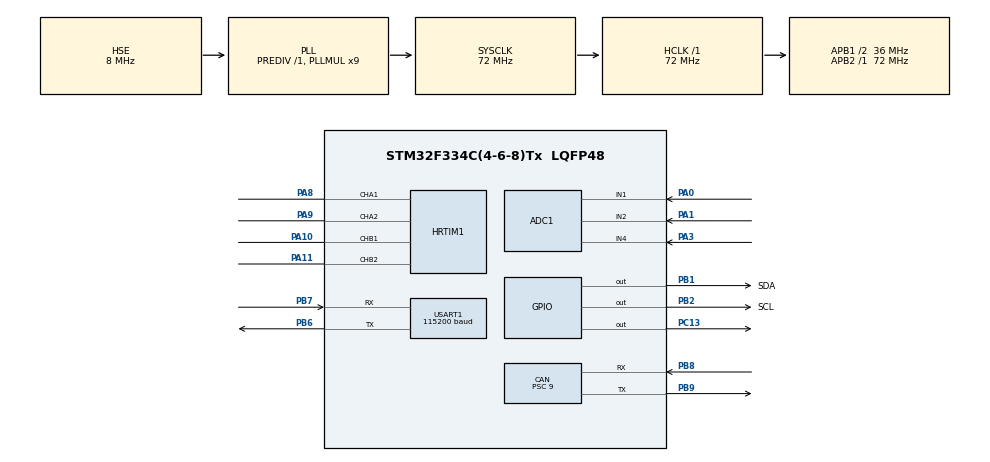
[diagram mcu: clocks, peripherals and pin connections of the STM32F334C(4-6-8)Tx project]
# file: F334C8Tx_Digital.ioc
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ADC1.Channel-0\#ChannelRegularConversion=ADC_CHANNEL_1
ADC1.Channel-5\#ChannelRegularConversion=ADC_CHANNEL_2
ADC1.Channel-6\#ChannelRegularConversion=ADC_CHANNEL_4
ADC1.ClockPrescaler=ADC_CLOCK_SYNC_PCLK_DIV4
ADC1.ContinuousConvMode=DISABLE
ADC1.DMAContinuousRequests=ENABLE
ADC1.DiscontinuousConvMode=DISABLE
ADC1.EOCSelection=ADC_EOC_SEQ_CONV
ADC1.EnableInjectedConversion=DISABLE
ADC1.ExternalTrigConv=ADC_EXTERNALTRIGCONVHRTIM_TRG1
ADC1.NbrOfConversion=3
ADC1.NbrOfConversionFlag=1
ADC1.Offset-0\#ChannelRegularConversion=0
ADC1.Offset-5\#ChannelRegularConversion=0
ADC1.Offset-6\#ChannelRegularConversion=0
ADC1.OffsetNumber-0\#ChannelRegularConversion=ADC_OFFSET_NONE
ADC1.OffsetNumber-5\#ChannelRegularConversion=ADC_OFFSET_NONE
ADC1.OffsetNumber-6\#ChannelRegularConversion=ADC_OFFSET_NONE
ADC1.Rank-0\#ChannelRegularConversion=1
ADC1.Rank-5\#ChannelRegularConversion=2
ADC1.Rank-6\#ChannelRegularConversion=3
ADC1.SamplingTime-0\#ChannelRegularConversion=ADC_SAMPLETIME_19CYCLES_5
ADC1.SamplingTime-5\#ChannelRegularConversion=ADC_SAMPLETIME_19CYCLES_5
ADC1.SamplingTime-6\#ChannelRegularConversion=ADC_SAMPLETIME_19CYCLES_5
ADC1.SamplingTimeOPAMP-5\#ChannelRegularConversion=ADC_SAMPLETIME_7CYCLES_5
ADC1.SamplingTimeOPAMP-6\#ChannelRegularConversion=ADC_SAMPLETIME_7CYCLES_5
ADC1.SubFamily=STM32F334x8
ADC1.master=1
CAN.BS1=CAN_BS1_2TQ
CAN.BS2=CAN_BS2_1TQ
CAN.CalculateBaudRate=1000000
CAN.CalculateTimeBit=1000.00
CAN.CalculateTimeQuantum=250.0
CAN.Prescaler=9
Dma.ADC1.0.Direction=DMA_PERIPH_TO_MEMORY
Dma.ADC1.0.Instance=DMA1_Channel1
Dma.ADC1.0.MemDataAlignment=DMA_MDATAALIGN_HALFWORD
Dma.ADC1.0.MemInc=DMA_MINC_ENABLE
Dma.ADC1.0.Mode=DMA_CIRCULAR
Dma.ADC1.0.PeriphDataAlignment=DMA_PDATAALIGN_HALFWORD
Dma.ADC1.0.PeriphInc=DMA_PINC_DISABLE
Dma.ADC1.0.Priority=DMA_PRIORITY_HIGH
Dma.Request0=ADC1
HRTIM1.ADCTrigger1_Source1=HRTIM_ADCTRIGGEREVENT13_MASTER_CMP3
HRTIM1.ADCTrigger_Id1=HRTIM_ADCTRIGGER_1
HRTIM1.CompareUnit1-MasterTimer=HRTIM_COMPAREUNIT_1
HRTIM1.CompareUnit1-Output_TA1TA2=__NULL
HRTIM1.CompareUnit2-MasterTimer=HRTIM_COMPAREUNIT_2
HRTIM1.CompareUnit3-MasterTimer=HRTIM_COMPAREUNIT_3
HRTIM1.CompareUnit3-Output_TA1TA2=HRTIM_COMPAREUNIT_3
HRTIM1.CompareUnit4-MasterTimer=HRTIM_COMPAREUNIT_4
HRTIM1.CompareValue1-MasterTimer=13600-400
HRTIM1.CompareValue2-MasterTimer=13600+400
HRTIM1.CompareValue3-MasterTimer=13600-4000
HRTIM1.CompareValue3-Output_TA1TA2=20400
HRTIM1.CompareValue4-MasterTimer=13600+4000
HRTIM1.DeadTimeInsertion-Output_TA1TA2=HRTIM_TIMDEADTIMEINSERTION_ENABLED
HRTIM1.DeadTimeInsertion-Output_TB1TB2=HRTIM_TIMDEADTIMEINSERTION_ENABLED
HRTIM1.FallingValue-Output_TA1TA2=100
HRTIM1.FallingValue-Output_TB1TB2=100
HRTIM1.NumberADCTriggerSource1=1
HRTIM1.NumberResetSource1-Output_TA1TA2=1
HRTIM1.NumberResetSource1-Output_TB1TB2=1
HRTIM1.NumberSetSource1-Output_TA1TA2=1
HRTIM1.NumberSetSource1-Output_TB1TB2=1
HRTIM1.NumberUpdateTrigger-Output_TA1TA2=1
HRTIM1.NumberUpdateTrigger-Output_TB1TB2=1
HRTIM1.ORingUpdateSource_ADCTrigger1=HRTIM_ADCTRIGGERUPDATE_MASTER
HRTIM1.Periode_MASTER=30720
HRTIM1.Periode_TA=30720
HRTIM1.Periode_TB=30720
HRTIM1.ResetOutput1_Source1-Output_TA1TA2=HRTIM_OUTPUTRESET_MASTERCMP2
HRTIM1.ResetOutput1_Source1-Output_TB1TB2=HRTIM_OUTPUTRESET_MASTERCMP4
HRTIM1.RisingValue-Output_TA1TA2=100
HRTIM1.RisingValue-Output_TB1TB2=100
HRTIM1.SetOutput1_Source1-Output_TA1TA2=HRTIM_OUTPUTSET_MASTERCMP1
HRTIM1.SetOutput1_Source1-Output_TB1TB2=HRTIM_OUTPUTSET_MASTERCMP3
HRTIM1.UpdateTrigger1-Output_TA1TA2=HRTIM_TIMUPDATETRIGGER_MASTER
HRTIM1.UpdateTrigger1-Output_TB1TB2=HRTIM_TIMUPDATETRIGGER_MASTER
Mcu.Family=STM32F3
Mcu.Name=STM32F334C(4-6-8)Tx
Mcu.Package=LQFP48
NVIC.PriorityGroup=NVIC_PRIORITYGROUP_4
NVIC.TIM6_DAC1_IRQn=true\:0\:0\:false\:false\:true\:true\:true
PA0.Mode=IN1-Single-Ended
PA0.Signal=ADC1_IN1
PA1.Mode=IN2-Single-Ended
PA1.Signal=ADC1_IN2
PA10.Mode=Output_TB1TB2
PA10.Signal=HRTIM1_CHB1
PA11.Mode=Output_TB1TB2
PA11.Signal=HRTIM1_CHB2
PA13.Mode=Serial_Wire
PA13.Signal=SYS_JTMS-SWDIO
PA14.Mode=Serial_Wire
PA14.Signal=SYS_JTCK-SWCLK
PA3.Mode=IN4-Single-Ended
PA3.Signal=ADC1_IN4
PA8.Mode=Output_TA1TA2
PA8.Signal=HRTIM1_CHA1
PA9.Mode=Output_TA1TA2
PA9.Signal=HRTIM1_CHA2
PB1.GPIO_Label=SDA
PB1.GPIO_Speed=GPIO_SPEED_FREQ_HIGH
PB1.Signal=GPIO_Output
PB2.GPIO_Label=SCL
PB2.GPIO_Speed=GPIO_SPEED_FREQ_HIGH
PB2.Signal=GPIO_Output
PB6.Mode=Asynchronous
PB6.Signal=USART1_TX
PB7.Mode=Asynchronous
PB7.Signal=USART1_RX
PB8.Mode=CAN_Activate
PB8.Signal=CAN_RX
PB9.Mode=CAN_Activate
PB9.Signal=CAN_TX
PC13.Signal=GPIO_Output
PF0\ /\ OSC_IN.Mode=HSE-External-Oscillator
PF0\ /\ OSC_IN.Signal=RCC_OSC_IN
PF1\ /\ OSC_OUT.Mode=HSE-External-Oscillator
PF1\ /\ OSC_OUT.Signal=RCC_OSC_OUT
ProjectManager.HeapSize=0x200
ProjectManager.StackSize=0x400
ProjectManager.TargetToolchain=MDK-ARM V5
RCC.AHBFreq_Value=72000000
RCC.APB1CLKDivider=RCC_HCLK_DIV2
RCC.APB1Freq_Value=36000000
RCC.APB1TimFreq_Value=72000000
RCC.APB2Freq_Value=72000000
RCC.APB2TimFreq_Value=72000000
RCC.CortexFreq_Value=72000000
RCC.HCLKFreq_Value=72000000
RCC.HRTIMSelection=RCC_HRTIM1CLK_PLLCLK
RCC.HSE_VALUE=8000000
RCC.HSI_VALUE=8000000
RCC.LSE_VALUE=32768
RCC.PLLMUL=RCC_PLL_MUL9
RCC.PLLSourceVirtual=RCC_PLLSOURCE_HSE
RCC.SYSCLKFreq_VALUE=72000000
RCC.SYSCLKSourceVirtual=RCC_SYSCLKSOURCE_PLLCLK
TIM6.Period=100-1
TIM6.Prescaler=72-1
USART1.BaudRate=115200
USART1.VirtualMode-Asynchronous=VM_ASYNC
VP_HRTIM1_VS_hrtimMasterTimerNoOutput.Mode=MasterTimer
VP_TIM6_VS_ClockSourceINT.Mode=Enable_Timer
board=custom

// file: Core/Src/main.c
/* USER CODE BEGIN Header */
/**
  ******************************************************************************
  * @file           : main.c
  * @brief          : Main program body
  ******************************************************************************
  * @attention
  *
  * <h2><center>&copy; Copyright (c) 2022 STMicroelectronics.
  * All rights reserved.</center></h2>
  *
  * This software component is licensed by ST under BSD 3-Clause license,
  * the "License"; You may not use this file except in compliance with the
  * License. You may obtain a copy of the License at:
  *                        opensource.org/licenses/BSD-3-Clause
  *
  ******************************************************************************
  */
/* USER CODE END Header */
#include "main.h"
#include "adc.h"
#include "can.h"
#include "dma.h"
#include "hrtim.h"
#include "hrtim.h"
#include "tim.h"
#include "usart.h"
#include "gpio.h"

void SystemClock_Config(void);

int main(void)
{

  /* MCU Configuration--------------------------------------------------------*/

  /* Reset of all peripherals, Initializes the Flash interface and the Systick. */
  HAL_Init();

  /* Configure the system clock */
  SystemClock_Config();

  /* Initialize all configured peripherals */
  MX_GPIO_Init();
  MX_DMA_Init();
  MX_ADC1_Init();
  MX_CAN_Init();
  MX_USART1_UART_Init();
  MX_HRTIM1_Init();
  MX_TIM6_Init();
  /* USER CODE BEGIN 2 */
	Software_I2C_GPIO_Init();

	buckboost_init();
	HAL_ADCEx_Calibration_Start(&hadc1,ADC_SINGLE_ENDED);
	//HAL_Delay(10);
	HAL_ADC_Start_DMA(&hadc1,(uint32_t*)adc1_in_buff,3);
	//HAL_ADCEx_InjectedStart(&hadc1);

	//HAL_ADCEx_Calibration_Start(&hadc2,ADC_SINGLE_ENDED);
	//HAL_Delay(10);
	//HAL_ADC_Start_DMA(&hadc2,(uint32_t*)adc2_in_buff,1);

	HAL_HRTIM_WaveformOutputStart(&hhrtim1, HRTIM_OUTPUT_TB1 | HRTIM_OUTPUT_TB2 | HRTIM_OUTPUT_TA1 | HRTIM_OUTPUT_TA2);

  HAL_HRTIM_WaveformCounterStart(&hhrtim1, HRTIM_TIMERID_TIMER_B | HRTIM_TIMERID_TIMER_A | HRTIM_TIMERID_MASTER);

	HAL_TIM_Base_Start_IT(&htim6);

  	OLED_Init();
 OLED_ShowChar(0, 0, 'A', FontSize8x16, 1);
  OLED_ShowStr(0, 2, (uint8_t *)"123abc!@#$^", FontSize6x8, 0);
  OLED_ShowCN(0, 6, 1, 1);
  OLED_LocalFill(70, 3, 80, 4, Bright);

  /* USER CODE END 2 */

  /* Infinite loop */
  while (1)
  {

    /* USER CODE BEGIN 3 */

	//	HAL_Delay(100);
  }
  /* USER CODE END 3 */
}

void SystemClock_Config(void)
{
  RCC_OscInitTypeDef RCC_OscInitStruct = {0};
  RCC_ClkInitTypeDef RCC_ClkInitStruct = {0};
  RCC_PeriphCLKInitTypeDef PeriphClkInit = {0};

  /** Initializes the RCC Oscillators according to the specified parameters
  * in the RCC_OscInitTypeDef structure.
  */
  RCC_OscInitStruct.OscillatorType = RCC_OSCILLATORTYPE_HSE;
  RCC_OscInitStruct.HSEState = RCC_HSE_ON;
  RCC_OscInitStruct.HSEPredivValue = RCC_HSE_PREDIV_DIV1;
  RCC_OscInitStruct.HSIState = RCC_HSI_ON;
  RCC_OscInitStruct.PLL.PLLState = RCC_PLL_ON;
  RCC_OscInitStruct.PLL.PLLSource = RCC_PLLSOURCE_HSE;
  RCC_OscInitStruct.PLL.PLLMUL = RCC_PLL_MUL9;
  if (HAL_RCC_OscConfig(&RCC_OscInitStruct) != HAL_OK)
  {
    Error_Handler();
  }
  /** Initializes the CPU, AHB and APB buses clocks
  */
  RCC_ClkInitStruct.ClockType = RCC_CLOCKTYPE_HCLK|RCC_CLOCKTYPE_SYSCLK
                              |RCC_CLOCKTYPE_PCLK1|RCC_CLOCKTYPE_PCLK2;
  RCC_ClkInitStruct.SYSCLKSource = RCC_SYSCLKSOURCE_PLLCLK;
  RCC_ClkInitStruct.AHBCLKDivider = RCC_SYSCLK_DIV1;
  RCC_ClkInitStruct.APB1CLKDivider = RCC_HCLK_DIV2;
  RCC_ClkInitStruct.APB2CLKDivider = RCC_HCLK_DIV1;

  if (HAL_RCC_ClockConfig(&RCC_ClkInitStruct, FLASH_LATENCY_2) != HAL_OK)
  {
    Error_Handler();
  }
  PeriphClkInit.PeriphClockSelection = RCC_PERIPHCLK_HRTIM1|RCC_PERIPHCLK_USART1;
  PeriphClkInit.Usart1ClockSelection = RCC_USART1CLKSOURCE_PCLK1;
  PeriphClkInit.Hrtim1ClockSelection = RCC_HRTIM1CLK_PLLCLK;
  if (HAL_RCCEx_PeriphCLKConfig(&PeriphClkInit) != HAL_OK)
  {
    Error_Handler();
  }
}

void Error_Handler(void)
{
  __disable_irq();
  while (1)
  {
  }
}

/************************ (C) COPYRIGHT STMicroelectronics *****END OF FILE****/
